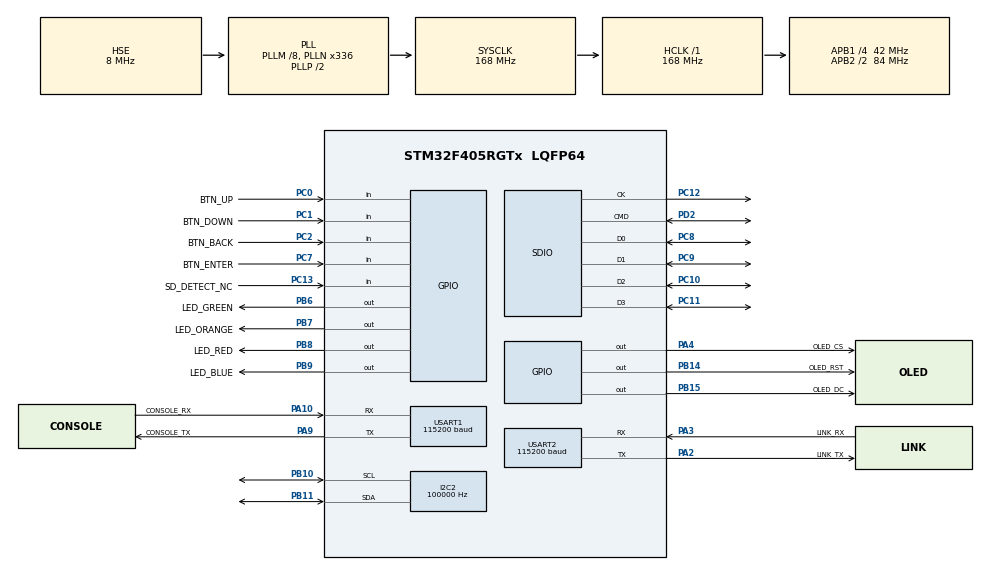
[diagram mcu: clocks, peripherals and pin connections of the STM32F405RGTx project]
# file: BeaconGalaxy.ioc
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Dma.Request0=SDIO_RX
Dma.Request1=SDIO_TX
Dma.SDIO_RX.0.Direction=DMA_PERIPH_TO_MEMORY
Dma.SDIO_RX.0.FIFOMode=DMA_FIFOMODE_ENABLE
Dma.SDIO_RX.0.FIFOThreshold=DMA_FIFO_THRESHOLD_FULL
Dma.SDIO_RX.0.Instance=DMA2_Stream3
Dma.SDIO_RX.0.MemBurst=DMA_MBURST_INC4
Dma.SDIO_RX.0.MemDataAlignment=DMA_MDATAALIGN_WORD
Dma.SDIO_RX.0.MemInc=DMA_MINC_ENABLE
Dma.SDIO_RX.0.Mode=DMA_PFCTRL
Dma.SDIO_RX.0.PeriphBurst=DMA_PBURST_INC4
Dma.SDIO_RX.0.PeriphDataAlignment=DMA_PDATAALIGN_WORD
Dma.SDIO_RX.0.PeriphInc=DMA_PINC_DISABLE
Dma.SDIO_RX.0.Priority=DMA_PRIORITY_HIGH
Dma.SDIO_TX.1.Direction=DMA_MEMORY_TO_PERIPH
Dma.SDIO_TX.1.FIFOMode=DMA_FIFOMODE_ENABLE
Dma.SDIO_TX.1.FIFOThreshold=DMA_FIFO_THRESHOLD_FULL
Dma.SDIO_TX.1.Instance=DMA2_Stream6
Dma.SDIO_TX.1.MemBurst=DMA_MBURST_INC4
Dma.SDIO_TX.1.MemDataAlignment=DMA_MDATAALIGN_WORD
Dma.SDIO_TX.1.MemInc=DMA_MINC_ENABLE
Dma.SDIO_TX.1.Mode=DMA_PFCTRL
Dma.SDIO_TX.1.PeriphBurst=DMA_PBURST_INC4
Dma.SDIO_TX.1.PeriphDataAlignment=DMA_PDATAALIGN_WORD
Dma.SDIO_TX.1.PeriphInc=DMA_PINC_DISABLE
Dma.SDIO_TX.1.Priority=DMA_PRIORITY_HIGH
FATFS.BSP.number=1
FATFS.USE_DMA_CODE_SD=1
FATFS._CODE_PAGE=437
FATFS._FS_REENTRANT=1
FATFS._MAX_LFN=255
FATFS._USE_FIND=1
FATFS._USE_LFN=2
FATFS._USE_STRFUNC=2
FATFS0.BSP.STBoard=false
FATFS0.BSP.api=Unknown
FATFS0.BSP.instance=PC13-ANTI_TAMP
FATFS0.BSP.ip=GPIO
FATFS0.BSP.mode=Input
FATFS0.BSP.name=Detect_SDIO
FATFS0.BSP.solution=PC13-ANTI_TAMP
FREERTOS.Tasks01=defaultTask,24,1024,StartDefaultTask,Default,NULL,Dynamic,NULL,NULL
FREERTOS.configCHECK_FOR_STACK_OVERFLOW=2
FREERTOS.configRECORD_STACK_HIGH_ADDRESS=1
FREERTOS.configTOTAL_HEAP_SIZE=60000
FREERTOS.configUSE_MALLOC_FAILED_HOOK=1
FREERTOS.configUSE_NEWLIB_REENTRANT=1
I2C2.ClockSpeed=100000
Mcu.Family=STM32F4
Mcu.Name=STM32F405RGTx
Mcu.Package=LQFP64
NVIC.DMA2_Stream3_IRQn=true\:5\:0\:false\:false\:true\:true\:false\:true\:true
NVIC.DMA2_Stream6_IRQn=true\:5\:0\:false\:false\:true\:true\:false\:true\:true
NVIC.PriorityGroup=NVIC_PRIORITYGROUP_4
NVIC.SDIO_IRQn=true\:5\:0\:false\:false\:true\:true\:true\:true\:true
NVIC.TIM6_DAC_IRQn=true\:15\:0\:false\:false\:true\:false\:false\:true\:true
NVIC.TimeBase=TIM6_DAC_IRQn
NVIC.TimeBaseIP=TIM6
NVIC.USART1_IRQn=true\:5\:0\:false\:false\:true\:true\:true\:true\:true
NVIC.USART2_IRQn=true\:5\:0\:false\:false\:true\:true\:true\:true\:true
PA10.GPIO_Label=CONSOLE_RX
PA10.Mode=Asynchronous
PA10.Signal=USART1_RX
PA13.Mode=Serial_Wire
PA13.Signal=SYS_JTMS-SWDIO
PA14.Mode=Serial_Wire
PA14.Signal=SYS_JTCK-SWCLK
PA2.GPIO_Label=LINK_TX
PA2.Mode=Asynchronous
PA2.Signal=USART2_TX
PA3.GPIO_Label=LINK_RX
PA3.Mode=Asynchronous
PA3.Signal=USART2_RX
PA4.GPIO_Label=OLED_CS
PA4.GPIO_Speed=GPIO_SPEED_FREQ_HIGH
PA4.PinState=GPIO_PIN_SET
PA4.Signal=GPIO_Output
PA9.GPIO_Label=CONSOLE_TX
PA9.Mode=Asynchronous
PA9.Signal=USART1_TX
PB10.Mode=I2C
PB10.Signal=I2C2_SCL
PB11.Mode=I2C
PB11.Signal=I2C2_SDA
PB14.GPIO_Label=OLED_RST
PB14.PinState=GPIO_PIN_SET
PB14.Signal=GPIO_Output
PB15.GPIO_Label=OLED_DC
PB15.GPIO_Speed=GPIO_SPEED_FREQ_HIGH
PB15.Signal=GPIO_Output
PB6.GPIO_Label=LED_GREEN
PB6.Signal=GPIO_Output
PB7.GPIO_Label=LED_ORANGE
PB7.Signal=GPIO_Output
PB8.GPIO_Label=LED_RED
PB8.Signal=GPIO_Output
PB9.GPIO_Label=LED_BLUE
PB9.Signal=GPIO_Output
PC0.GPIO_Label=BTN_UP
PC0.GPIO_PuPd=GPIO_PULLDOWN
PC0.Signal=GPIO_Input
PC1.GPIO_Label=BTN_DOWN
PC1.GPIO_PuPd=GPIO_PULLDOWN
PC1.Signal=GPIO_Input
PC10.Mode=SD_4_bits_Wide_bus
PC10.Signal=SDIO_D2
PC11.Mode=SD_4_bits_Wide_bus
PC11.Signal=SDIO_D3
PC12.Mode=SD_4_bits_Wide_bus
PC12.Signal=SDIO_CK
PC13-ANTI_TAMP.GPIO_Label=SD_DETECT_NC
PC13-ANTI_TAMP.GPIO_PuPd=GPIO_PULLDOWN
PC13-ANTI_TAMP.Signal=GPIO_Input
PC2.GPIO_Label=BTN_BACK
PC2.GPIO_PuPd=GPIO_PULLDOWN
PC2.Signal=GPIO_Input
PC7.GPIO_Label=BTN_ENTER
PC7.GPIO_PuPd=GPIO_PULLDOWN
PC7.Signal=GPIO_Input
PC8.Mode=SD_4_bits_Wide_bus
PC8.Signal=SDIO_D0
PC9.Mode=SD_4_bits_Wide_bus
PC9.Signal=SDIO_D1
PD2.Mode=SD_4_bits_Wide_bus
PD2.Signal=SDIO_CMD
PH0-OSC_IN.Mode=HSE-External-Oscillator
PH0-OSC_IN.Signal=RCC_OSC_IN
PH1-OSC_OUT.Mode=HSE-External-Oscillator
PH1-OSC_OUT.Signal=RCC_OSC_OUT
ProjectManager.HeapSize=0x400
ProjectManager.StackSize=0x800
ProjectManager.TargetToolchain=CMake
RCC.AHBFreq_Value=168000000
RCC.APB1CLKDivider=RCC_HCLK_DIV4
RCC.APB1Freq_Value=42000000
RCC.APB1TimFreq_Value=84000000
RCC.APB2CLKDivider=RCC_HCLK_DIV2
RCC.APB2Freq_Value=84000000
RCC.APB2TimFreq_Value=168000000
RCC.CortexFreq_Value=168000000
RCC.HCLKFreq_Value=168000000
RCC.HSE_VALUE=8000000
RCC.HSI_VALUE=16000000
RCC.LSE_VALUE=32768
RCC.PLLM=8
RCC.PLLN=336
RCC.PLLQ=7
RCC.PLLSourceVirtual=RCC_PLLSOURCE_HSE
RCC.SYSCLKFreq_VALUE=168000000
RCC.SYSCLKSource=RCC_SYSCLKSOURCE_PLLCLK
RCC.VCOOutputFreq_Value=336000000
SDIO.WideMode=SDIO_BUS_WIDE_4B
STMicroelectronics.X-CUBE-TOUCHGFX.4.27.0.ApplicationCcGraphicsJjApplication=TouchGFXOoGenerator
STMicroelectronics.X-CUBE-TOUCHGFX.4.27.0.tgfx_buffering_strategy=Single
STMicroelectronics.X-CUBE-TOUCHGFX.4.27.0.tgfx_custom_height=48
STMicroelectronics.X-CUBE-TOUCHGFX.4.27.0.tgfx_custom_width=64
STMicroelectronics.X-CUBE-TOUCHGFX.4.27.0.tgfx_display_interface=disp_custom
STMicroelectronics.X-CUBE-TOUCHGFX.4.27.0.tgfx_hardware_accelerator=dma_none
STMicroelectronics.X-CUBE-TOUCHGFX.4.27.0.tgfx_location=Allocate
STMicroelectronics.X-CUBE-TOUCHGFX.4.27.0.tgfx_oswrapper=CMSIS V2
STMicroelectronics.X-CUBE-TOUCHGFX.4.27.0.tgfx_pixel_format=BW\:1
STMicroelectronics.X-CUBE-TOUCHGFX.4.27.0.tgfx_vsync=vsync_custom
STMicroelectronics.X-CUBE-TOUCHGFX.4.27.0_IsPackSelfContextualization=true
USART1.BaudRate=115200
USART1.VirtualMode=VM_ASYNC
USART2.BaudRate=115200
USART2.VirtualMode=VM_ASYNC
VP_CRC_VS_CRC.Mode=CRC_Activate
VP_FATFS_VS_SDIO.Mode=SDIO
VP_FREERTOS_VS_CMSIS_V2.Mode=CMSIS_V2
VP_RNG_VS_RNG.Mode=RNG_Activate
VP_STMicroelectronics.X-CUBE-TOUCHGFX_VS_GraphicsJjApplication_4.27.0.Mode=GraphicsJjApplication
VP_SYS_VS_tim6.Mode=TIM6
board=custom

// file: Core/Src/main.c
/* USER CODE BEGIN Header */
/**
  ******************************************************************************
  * @file           : main.c
  * @brief          : Main program body
  ******************************************************************************
  * @attention
  *
  * Copyright (c) 2026 STMicroelectronics.
  * All rights reserved.
  *
  * This software is licensed under terms that can be found in the LICENSE file
  * in the root directory of this software component.
  * If no LICENSE file comes with this software, it is provided AS-IS.
  *
  ******************************************************************************
  */
/* USER CODE END Header */
#include "main.h"
#include "cmsis_os.h"
#include "crc.h"
#include "dma.h"
#include "fatfs.h"
#include "i2c.h"
#include "rng.h"
#include "sdio.h"
#include "usart.h"
#include "gpio.h"
#include "app_touchgfx.h"

void SystemClock_Config(void);
void MX_FREERTOS_Init(void);

int main(void)
{

  /* MCU Configuration--------------------------------------------------------*/

  /* Reset of all peripherals, Initializes the Flash interface and the Systick. */
  HAL_Init();

  /* Configure the system clock */
  SystemClock_Config();

  /* Initialize all configured peripherals */
  MX_GPIO_Init();
  MX_DMA_Init();
  MX_CRC_Init();
  MX_I2C2_Init();
  MX_RNG_Init();
  MX_SDIO_SD_Init();
  MX_USART1_UART_Init();
  MX_USART2_UART_Init();
  MX_FATFS_Init();
  MX_TouchGFX_Init();
  /* Call PreOsInit function */
  MX_TouchGFX_PreOSInit();

  /* Init scheduler */
  osKernelInitialize();  /* Call init function for freertos objects (in cmsis_os2.c) */
  MX_FREERTOS_Init();

  /* Start scheduler */
  osKernelStart();

  /* We should never get here as control is now taken by the scheduler */

  /* Infinite loop */
  while (1)
  {

  }
}

void SystemClock_Config(void)
{
  RCC_OscInitTypeDef RCC_OscInitStruct = {0};
  RCC_ClkInitTypeDef RCC_ClkInitStruct = {0};

  /** Configure the main internal regulator output voltage
  */
  __HAL_RCC_PWR_CLK_ENABLE();
  __HAL_PWR_VOLTAGESCALING_CONFIG(PWR_REGULATOR_VOLTAGE_SCALE1);

  /** Initializes the RCC Oscillators according to the specified parameters
  * in the RCC_OscInitTypeDef structure.
  */
  RCC_OscInitStruct.OscillatorType = RCC_OSCILLATORTYPE_HSE;
  RCC_OscInitStruct.HSEState = RCC_HSE_ON;
  RCC_OscInitStruct.PLL.PLLState = RCC_PLL_ON;
  RCC_OscInitStruct.PLL.PLLSource = RCC_PLLSOURCE_HSE;
  RCC_OscInitStruct.PLL.PLLM = 8;
  RCC_OscInitStruct.PLL.PLLN = 336;
  RCC_OscInitStruct.PLL.PLLP = RCC_PLLP_DIV2;
  RCC_OscInitStruct.PLL.PLLQ = 7;
  if (HAL_RCC_OscConfig(&RCC_OscInitStruct) != HAL_OK)
  {
    Error_Handler();
  }

  /** Initializes the CPU, AHB and APB buses clocks
  */
  RCC_ClkInitStruct.ClockType = RCC_CLOCKTYPE_HCLK|RCC_CLOCKTYPE_SYSCLK
                              |RCC_CLOCKTYPE_PCLK1|RCC_CLOCKTYPE_PCLK2;
  RCC_ClkInitStruct.SYSCLKSource = RCC_SYSCLKSOURCE_PLLCLK;
  RCC_ClkInitStruct.AHBCLKDivider = RCC_SYSCLK_DIV1;
  RCC_ClkInitStruct.APB1CLKDivider = RCC_HCLK_DIV4;
  RCC_ClkInitStruct.APB2CLKDivider = RCC_HCLK_DIV2;

  if (HAL_RCC_ClockConfig(&RCC_ClkInitStruct, FLASH_LATENCY_5) != HAL_OK)
  {
    Error_Handler();
  }
}

void HAL_TIM_PeriodElapsedCallback(TIM_HandleTypeDef *htim)
{
  if (htim->Instance == TIM6)
  {
    HAL_IncTick();
  }
}

void Error_Handler(void)
{
  __disable_irq();
  while (1)
  {
  }
}

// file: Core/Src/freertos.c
/* USER CODE BEGIN Header */
/**
  ******************************************************************************
  * File Name          : freertos.c
  * Description        : Code for freertos applications
  ******************************************************************************
  * @attention
  *
  * Copyright (c) 2026 STMicroelectronics.
  * All rights reserved.
  *
  * This software is licensed under terms that can be found in the LICENSE file
  * in the root directory of this software component.
  * If no LICENSE file comes with this software, it is provided AS-IS.
  *
  ******************************************************************************
  */
/* USER CODE END Header */

#include "FreeRTOS.h"
#include "task.h"
#include "main.h"
#include "cmsis_os.h"

/* USER CODE BEGIN Includes */
#include "app_main.h"
#include "app_hal.h"
/* USER CODE END Includes */

/* Definitions for defaultTask */
osThreadId_t defaultTaskHandle;
const osThreadAttr_t defaultTask_attributes = {
  .name = "defaultTask",
  .stack_size = 1024 * 4,
  .priority = (osPriority_t) osPriorityNormal,
};

void StartDefaultTask(void *argument);

void MX_FREERTOS_Init(void); /* (MISRA C 2004 rule 8.1) */

/* Hook prototypes */
void vApplicationStackOverflowHook(xTaskHandle xTask, signed char *pcTaskName);
void vApplicationMallocFailedHook(void);

/* USER CODE BEGIN 4 */
void vApplicationStackOverflowHook(xTaskHandle xTask, signed char *pcTaskName)
{
   /* Run time stack overflow checking is performed if
   configCHECK_FOR_STACK_OVERFLOW is defined to 1 or 2. This hook function is
   called if a stack overflow is detected. */
  (void)xTask;
  (void)pcTaskName;
  taskDISABLE_INTERRUPTS();
  HAL_GPIO_WritePin(LED_RED_GPIO_Port, LED_RED_Pin, GPIO_PIN_SET);
  for (;;) { }
}
/* USER CODE END 4 */

/* USER CODE BEGIN 5 */
void vApplicationMallocFailedHook(void)
{
   /* vApplicationMallocFailedHook() will only be called if
   configUSE_MALLOC_FAILED_HOOK is set to 1 in FreeRTOSConfig.h. It is a hook
   function that will get called if a call to pvPortMalloc() fails.
   pvPortMalloc() is called internally by the kernel whenever a task, queue,
   timer or semaphore is created. It is also called by various parts of the
   demo application. If heap_1.c or heap_2.c are used, then the size of the
   heap available to pvPortMalloc() is defined by configTOTAL_HEAP_SIZE in
   FreeRTOSConfig.h, and the xPortGetFreeHeapSize() API function can be used
   to query the size of free heap space that remains (although it does not
   provide information on how the remaining heap might be fragmented). */
  taskDISABLE_INTERRUPTS();
  HAL_GPIO_WritePin(LED_RED_GPIO_Port, LED_RED_Pin, GPIO_PIN_SET);
  for (;;) { }
}
/* USER CODE END 5 */

void MX_FREERTOS_Init(void) {

  /* Create the thread(s) */
  /* creation of defaultTask */
  defaultTaskHandle = osThreadNew(StartDefaultTask, NULL, &defaultTask_attributes);

}

void StartDefaultTask(void *argument)
{
  /* USER CODE BEGIN StartDefaultTask */
  App_Init();
  App_Run();   /* App task loop, never returns */
  /* USER CODE END StartDefaultTask */
}
